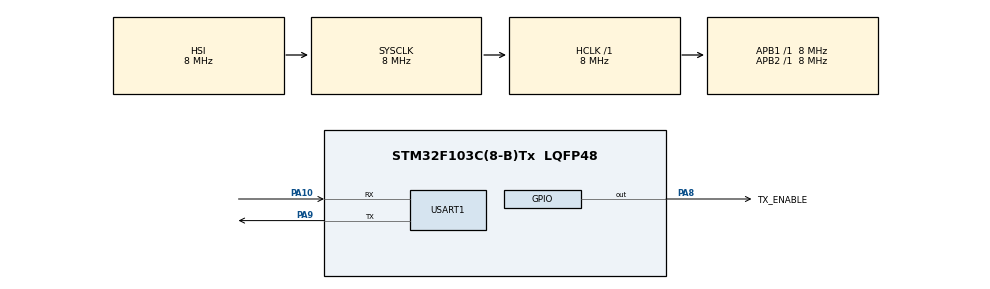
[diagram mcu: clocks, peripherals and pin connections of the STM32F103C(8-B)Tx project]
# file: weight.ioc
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Mcu.Family=STM32F1
Mcu.Name=STM32F103C(8-B)Tx
Mcu.Package=LQFP48
NVIC.PriorityGroup=NVIC_PRIORITYGROUP_4
PA10.Mode=Asynchronous
PA10.Signal=USART1_RX
PA8.GPIO_Label=TX_ENABLE
PA8.Signal=GPIO_Output
PA9.Mode=Asynchronous
PA9.Signal=USART1_TX
ProjectManager.HeapSize=0x200
ProjectManager.StackSize=0x400
ProjectManager.TargetToolchain=STM32CubeIDE
RCC.AHBFreq_Value=8000000
RCC.APB1Freq_Value=8000000
RCC.APB1TimCLKDivider=1
RCC.APB1TimFreq_Value=8000000
RCC.APB2Freq_Value=8000000
RCC.APB2TimFreq_Value=8000000
RCC.HCLKFreq_Value=8000000
RCC.SYSCLKFreq_VALUE=8000000
RCC.USBFreq_Value=8000000
TIM3.Period=49
TIM3.Prescaler=72-1
USART1.VirtualMode=VM_ASYNC
VP_SYS_VS_ND.Mode=No_Debug
VP_TIM3_VS_ClockSourceINT.Mode=Internal
board=custom

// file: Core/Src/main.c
/* USER CODE BEGIN Header */
/**
  ******************************************************************************
  * @file           : main.c
  * @brief          : Main program body
  ******************************************************************************
  * @attention
  *
  * Copyright (c) 2024 STMicroelectronics.
  * All rights reserved.
  *
  * This software is licensed under terms that can be found in the LICENSE file
  * in the root directory of this software component.
  * If no LICENSE file comes with this software, it is provided AS-IS.
  *
  ******************************************************************************
  */
/* USER CODE END Header */
#include "main.h"

/* USER CODE BEGIN Includes */
#include "mb.h"
#include "mbport.h"
#include "hx711.h"
/* USER CODE END Includes */

TIM_HandleTypeDef htim3;

UART_HandleTypeDef huart1;

void SystemClock_Config(void);
static void MX_GPIO_Init(void);
static void MX_TIM3_Init(void);
static void MX_USART1_UART_Init(void);

/* USER CODE BEGIN 0 */
#define REG_INPUT_START 1000
#define REG_INPUT_NREGS 2
#define REG_HOLDING_START 2000
#define REG_HOLDING_NREGS 2

static USHORT   usRegInputStart = REG_INPUT_START;
static USHORT   usRegInputBuf[REG_INPUT_NREGS];
static USHORT   usRegHoldingStart = REG_HOLDING_START;
static USHORT   usRegHoldingBuf[REG_HOLDING_NREGS];
/* USER CODE END 0 */

int main(void)
{

  /* MCU Configuration--------------------------------------------------------*/

  /* Reset of all peripherals, Initializes the Flash interface and the Systick. */
  HAL_Init();

  /* Configure the system clock */
  SystemClock_Config();

  /* Initialize all configured peripherals */
  MX_GPIO_Init();
  MX_TIM3_Init();
  MX_USART1_UART_Init();
  /* USER CODE BEGIN 2 */
  eMBInit( MB_RTU, 0x20, 0, 115200, MB_PAR_NONE );
  Modbus_HTIM_Init(&htim3);
  Modbus_UART_Init(&huart1, TX_ENABLE_GPIO_Port, TX_ENABLE_Pin);
  eMBEnable(  );
  /* USER CODE END 2 */

  /* Infinite loop */
  /* USER CODE BEGIN WHILE */
  while (1)
  {
	  (void)eMBPoll();
    /* USER CODE END WHILE */

  }
}

void SystemClock_Config(void)
{
  RCC_OscInitTypeDef RCC_OscInitStruct = {0};
  RCC_ClkInitTypeDef RCC_ClkInitStruct = {0};

  /** Initializes the RCC Oscillators according to the specified parameters
  * in the RCC_OscInitTypeDef structure.
  */
  RCC_OscInitStruct.OscillatorType = RCC_OSCILLATORTYPE_HSI;
  RCC_OscInitStruct.HSIState = RCC_HSI_ON;
  RCC_OscInitStruct.HSICalibrationValue = RCC_HSICALIBRATION_DEFAULT;
  RCC_OscInitStruct.PLL.PLLState = RCC_PLL_NONE;
  if (HAL_RCC_OscConfig(&RCC_OscInitStruct) != HAL_OK)
  {
    Error_Handler();
  }

  /** Initializes the CPU, AHB and APB buses clocks
  */
  RCC_ClkInitStruct.ClockType = RCC_CLOCKTYPE_HCLK|RCC_CLOCKTYPE_SYSCLK
                              |RCC_CLOCKTYPE_PCLK1|RCC_CLOCKTYPE_PCLK2;
  RCC_ClkInitStruct.SYSCLKSource = RCC_SYSCLKSOURCE_HSI;
  RCC_ClkInitStruct.AHBCLKDivider = RCC_SYSCLK_DIV1;
  RCC_ClkInitStruct.APB1CLKDivider = RCC_HCLK_DIV1;
  RCC_ClkInitStruct.APB2CLKDivider = RCC_HCLK_DIV1;

  if (HAL_RCC_ClockConfig(&RCC_ClkInitStruct, FLASH_LATENCY_0) != HAL_OK)
  {
    Error_Handler();
  }
}

static void MX_TIM3_Init(void)
{

  TIM_ClockConfigTypeDef sClockSourceConfig = {0};
  TIM_MasterConfigTypeDef sMasterConfig = {0};

  htim3.Instance = TIM3;
  htim3.Init.Prescaler = 72-1;
  htim3.Init.CounterMode = TIM_COUNTERMODE_UP;
  htim3.Init.Period = 49;
  htim3.Init.ClockDivision = TIM_CLOCKDIVISION_DIV1;
  htim3.Init.AutoReloadPreload = TIM_AUTORELOAD_PRELOAD_DISABLE;
  if (HAL_TIM_Base_Init(&htim3) != HAL_OK)
  {
    Error_Handler();
  }
  sClockSourceConfig.ClockSource = TIM_CLOCKSOURCE_INTERNAL;
  if (HAL_TIM_ConfigClockSource(&htim3, &sClockSourceConfig) != HAL_OK)
  {
    Error_Handler();
  }
  sMasterConfig.MasterOutputTrigger = TIM_TRGO_RESET;
  sMasterConfig.MasterSlaveMode = TIM_MASTERSLAVEMODE_DISABLE;
  if (HAL_TIMEx_MasterConfigSynchronization(&htim3, &sMasterConfig) != HAL_OK)
  {
    Error_Handler();
  }

}

static void MX_USART1_UART_Init(void)
{

  huart1.Instance = USART1;
  huart1.Init.BaudRate = 115200;
  huart1.Init.WordLength = UART_WORDLENGTH_8B;
  huart1.Init.StopBits = UART_STOPBITS_1;
  huart1.Init.Parity = UART_PARITY_NONE;
  huart1.Init.Mode = UART_MODE_TX_RX;
  huart1.Init.HwFlowCtl = UART_HWCONTROL_NONE;
  huart1.Init.OverSampling = UART_OVERSAMPLING_16;
  if (HAL_UART_Init(&huart1) != HAL_OK)
  {
    Error_Handler();
  }

}

static void MX_GPIO_Init(void)
{
  GPIO_InitTypeDef GPIO_InitStruct = {0};

  /* GPIO Ports Clock Enable */
  __HAL_RCC_GPIOA_CLK_ENABLE();

  /*Configure GPIO pin Output Level */
  HAL_GPIO_WritePin(TX_ENABLE_GPIO_Port, TX_ENABLE_Pin, GPIO_PIN_RESET);

  /*Configure GPIO pin : TX_ENABLE_Pin */
  GPIO_InitStruct.Pin = TX_ENABLE_Pin;
  GPIO_InitStruct.Mode = GPIO_MODE_OUTPUT_PP;
  GPIO_InitStruct.Pull = GPIO_NOPULL;
  GPIO_InitStruct.Speed = GPIO_SPEED_FREQ_LOW;
  HAL_GPIO_Init(TX_ENABLE_GPIO_Port, &GPIO_InitStruct);

}

/* USER CODE BEGIN 4 */
eMBErrorCode
eMBRegInputCB( UCHAR * pucRegBuffer, USHORT usAddress, USHORT usNRegs )
{
    eMBErrorCode    eStatus = MB_ENOERR;
    int             iRegIndex;

    if( ( usAddress >= REG_INPUT_START )
        && ( usAddress + usNRegs <= REG_INPUT_START + REG_INPUT_NREGS ) )
    {
        iRegIndex = ( int )( usAddress - usRegInputStart );
        while( usNRegs > 0 )
        {
            *pucRegBuffer++ = ( unsigned char )( usRegInputBuf[iRegIndex] >> 8 );
            *pucRegBuffer++ = ( unsigned char )( usRegInputBuf[iRegIndex] & 0xFF );
            iRegIndex++;
            usNRegs--;
        }
    }
    else
    {
        eStatus = MB_ENOREG;
    }

    return eStatus;
}

eMBErrorCode
eMBRegHoldingCB( UCHAR * pucRegBuffer, USHORT usAddress, USHORT usNRegs, eMBRegisterMode eMode )
{
    eMBErrorCode    eStatus = MB_ENOERR;
    int             iRegIndex;

    if( ( usAddress >= REG_HOLDING_START ) &&
        ( usAddress + usNRegs <= REG_HOLDING_START + REG_HOLDING_NREGS ) )
    {
        iRegIndex = ( int )( usAddress - usRegHoldingStart );
        switch ( eMode )
        {
            /* Pass current register values to the protocol stack. */
        case MB_REG_READ:
            while( usNRegs > 0 )
            {
                *pucRegBuffer++ = ( UCHAR ) ( usRegHoldingBuf[iRegIndex] >> 8 );
                *pucRegBuffer++ = ( UCHAR ) ( usRegHoldingBuf[iRegIndex] & 0xFF );
                iRegIndex++;
                usNRegs--;
            }
            break;

            /* Update current register values with new values from the
             * protocol stack. */
        case MB_REG_WRITE:
            while( usNRegs > 0 )
            {
                usRegHoldingBuf[iRegIndex] = *pucRegBuffer++ << 8;
                usRegHoldingBuf[iRegIndex] |= *pucRegBuffer++;
                iRegIndex++;
                usNRegs--;
            }
        }
    }
    else
    {
        eStatus = MB_ENOREG;
    }
    return eStatus;
}

eMBErrorCode
eMBRegCoilsCB( UCHAR * pucRegBuffer, USHORT usAddress, USHORT usNCoils, eMBRegisterMode eMode )
{
    return MB_ENOREG;
}

eMBErrorCode
eMBRegDiscreteCB( UCHAR * pucRegBuffer, USHORT usAddress, USHORT usNDiscrete )
{
    return MB_ENOREG;
}

/* USER CODE END 4 */

void Error_Handler(void)
{
  __disable_irq();
  while (1)
  {
  }
}
